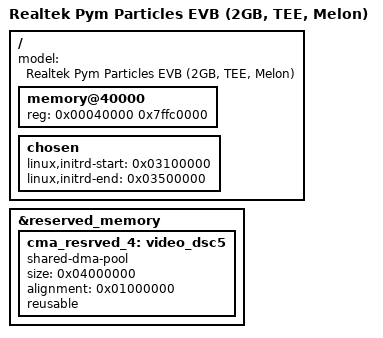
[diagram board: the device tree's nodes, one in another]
// SPDX-License-Identifier: (GPL-2.0-or-later OR BSD-2-Clause)
/*
 * Realtek RTD13xx SoC family
 *
 * Copyright (c) 2019-2022 Realtek Semiconductor Corp.
 */

/dts-v1/;

#include "rtd1319-pymparticles.dtsi"

/ {
	model = "Realtek Pym Particles EVB (2GB, TEE, Melon)";

	memory@40000 {
		device_type = "memory";
		reg = <0x00040000 0x7ffc0000>; /* 2 GiB */
	};

	chosen {
		linux,initrd-start = <0x03100000>;
		linux,initrd-end = <0x03500000>;
	};
};

&reserved_memory{
	cma_resrved_4:video_dsc5 {
		compatible = "shared-dma-pool";
		size = <0x04000000>;
		alignment = <0x01000000>;
		reusable;
	};
};
